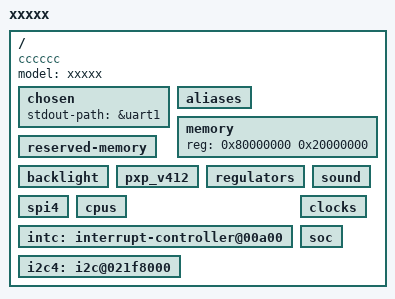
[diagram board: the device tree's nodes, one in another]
/dts-v1/;

#include ".h"
#include ".dtsi" //晶片內部的外設資訊

/ {
    /* skeleton.dtsi*/
    #address-cells = <1>;
    #size-cells = <1>;
    chosen { };
    aliases { };
    memory { 
        device_type = "memory"; 
        reg = <0 0>; 
    };
    /* 骨架 會被後面追加進來的取代*/

    model = "xxxxx";    //屬性名 = "屬性值"
    compatible = "cccccc", "aaaaaaa";   //屬性

    //子節點
    chosen {
        stdout-path = &uart1;   //屬性
    };

    //描述板子的內存
    memory {
        reg = <0x80000000 0x20000000>;
        //reg = <起始地址 size>
    };

    reserved-memory {

    };

    backlight {

    };

    pxp_v412 {

    };

    regulators {

    };

    sound {

    };

    spi4 {

    };

    cpus {

    };

    //描述中斷
    intc: interrupt-controller@00a00 {
        //標籤: 名字: 用途是不用打一長串，用標籤就可以了
    };

    i2c4: i2c@021f8000 {
        //021f8000是i2c4的地址
        
    };

    clocks {

    };

    soc {

    };
};

